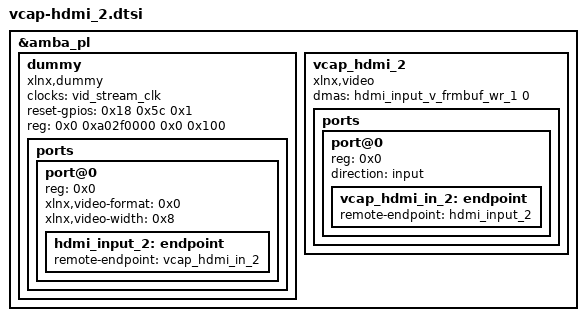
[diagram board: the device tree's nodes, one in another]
&amba_pl {

	dummy {
		compatible = "xlnx,dummy";
		#address-cells = <0x1>;
		#size-cells = <0x0>;
		clocks = <&vid_stream_clk>;
		reset-gpios = <0x18 0x5c 0x1>;
		reg = <0x0 0xa02f0000 0x0 0x100>;
            
		ports {
			#address-cells = <0x1>;
                	#size-cells = <0x0>;

	                port@0 {
				reg = <0x0>;
				xlnx,video-format = <0x0>;
				xlnx,video-width = <0x8>;

				hdmi_input_2:endpoint {
					remote-endpoint = <&vcap_hdmi_in_2>;
				};
			};
		};
	};

	vcap_hdmi_2 {
		compatible = "xlnx,video";
		dmas = <&hdmi_input_v_frmbuf_wr_1 0>;
		dma-names = "port0";

		ports {
			#address-cells = <0x1>;
			#size-cells = <0x0>;

			port@0 {
				reg = <0x0>;
				direction = "input";

				vcap_hdmi_in_2:endpoint {
					remote-endpoint = <&hdmi_input_2>;
				};
			};
		};
	};

};
